AUTOSAR XML (schema 00049)
package /af_EvTi_Component
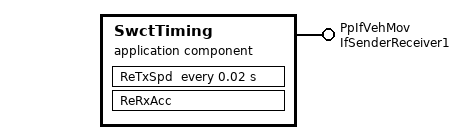
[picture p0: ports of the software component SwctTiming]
  application sw component type SwctTiming
    provide port PpIfVehMov: provided-interface=IfSenderReceiver1
    behavior IbhSwctTiming
      runnable ReTxSpd
        data-send-points:
          access SendPoint_PpIfVehMov_Spd: accessed-variable=PpIfVehMov.Spd
      runnable ReRxAcc
        data-read-access:
          access DataReadAccess_PpIfVehMov_Acc: accessed-variable=PpIfVehMov.Acc
      timing event EvTiSpd_20ms: start-on-event=ReTxSpd, period=0.02
